# STM32F413 register map
File version: 1.9
CPU: CM4 r0p1, little endian, MPU, FPU, 4 interrupt priority bits
Registers are 32-bit, read-write, reset 0x0 unless marked. A register's access mark holds for its fields unless they carry their own. Offsets are from the block's base; [hi:lo] are bit positions; lines under a group give offsets from that group; {n}, {i} and the like mark numbered series; 'fields as' and 'values as' point back to an identical list.

## IWDG — Independent watchdog
Base 0x40003000
0x00 KR 16-bit wo — Key register
  [15:0] KEY — Key value
    0x5555=Unlock (Enable access to PR, RLR and WINR registers); 0xAAAA=Feed watchdog with RLR register value; 0xCCCC=Start the watchdog
0x04 PR 16-bit — Prescaler register
  [2:0] PR — Prescaler divider
    0=DivideBy4 (Divider /4); 1=DivideBy8 (Divider /8); 2=DivideBy16 (Divider /16); 3=DivideBy32 (Divider /32); 4=DivideBy64 (Divider /64); 5=DivideBy128 (Divider /128); other=DivideBy256 (Divider /256)
0x08 RLR 16-bit reset 0xFFF — Reload register
  [11:0] RL — Watchdog counter reload value
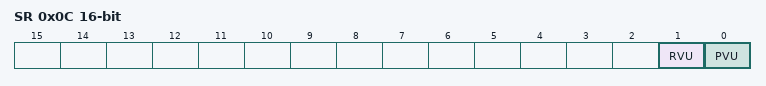
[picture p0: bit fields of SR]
0x0C SR 16-bit ro — Status register
  [1] RVU — Watchdog counter reload value update
  [0] PVU — Watchdog prescaler value update

## RNG — Random number generator
Base 0x50060800
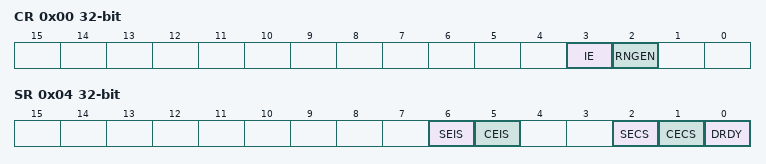
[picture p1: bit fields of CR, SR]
0x00 CR — control register
  [3] IE — Interrupt enable
  [2] RNGEN — Random number generator enable
0x04 SR access per field — status register
  [6] SEIS rw — Seed error interrupt status
  [5] CEIS rw — Clock error interrupt status
  [2] SECS ro — Seed error current status
  [1] CECS ro — Clock error current status
  [0] DRDY ro — Data ready
0x08 DR ro — data register
  [31:0] RNDATA — Random data

## OTG_FS_HOST — USB on the go full speed
Base 0x50000400
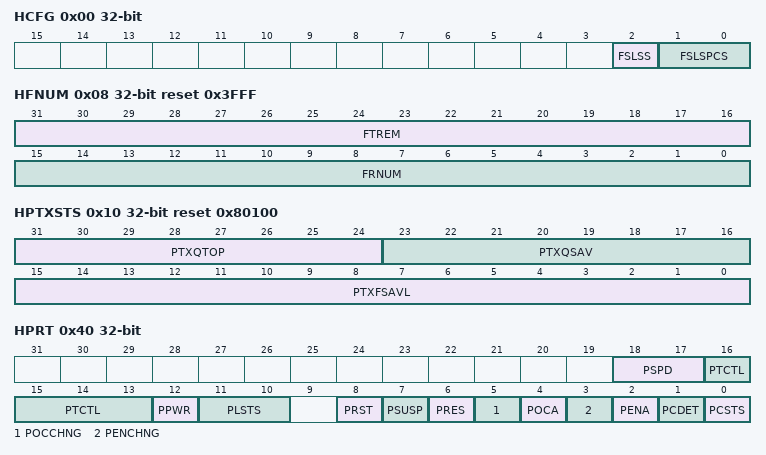
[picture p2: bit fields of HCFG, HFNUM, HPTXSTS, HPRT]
0x00 HCFG — OTG_FS host configuration register (OTG_FS_HCFG)
  [2] FSLSS — FS- and LS-only support
  [1:0] FSLSPCS — FS/LS PHY clock select
0x04 HFIR reset 0xEA60 — OTG_FS Host frame interval register
  [15:0] FRIVL — Frame interval
0x08 HFNUM ro reset 0x3FFF — OTG_FS host frame number/frame time remaining register (OTG_FS_HFNUM)
  [31:16] FTREM — Frame time remaining
  [15:0] FRNUM — Frame number
0x10 HPTXSTS access per field reset 0x80100 — OTG_FS_Host periodic transmit FIFO/queue status register (OTG_FS_HPTXSTS)
  [31:24] PTXQTOP ro — Top of the periodic transmit request queue
  [23:16] PTXQSAV ro — Periodic transmit request queue space available
  [15:0] PTXFSAVL rw — Periodic transmit data FIFO space available
0x14 HAINT ro — OTG_FS Host all channels interrupt register
  [15:0] HAINT — Channel interrupts
0x18 HAINTMSK — OTG_FS host all channels interrupt mask register
  [15:0] HAINTM — Channel interrupt mask
0x40 HPRT access per field — OTG_FS host port control and status register (OTG_FS_HPRT)
  [18:17] PSPD ro — Port speed
  [16:13] PTCTL rw — Port test control
  [12] PPWR rw — Port power
  [11:10] PLSTS ro — Port line status
  [8] PRST rw — Port reset
  [7] PSUSP rw — Port suspend
  [6] PRES rw — Port resume
  [5] POCCHNG rw — Port overcurrent change
  [4] POCA ro — Port overcurrent active
  [3] PENCHNG rw — Port enable/disable change
  [2] PENA rw — Port enable
  [1] PCDET rw — Port connect detected
  [0] PCSTS ro — Port connect status
{0x100+0x20*i} HC{i} (i=0..11) group — Host channel
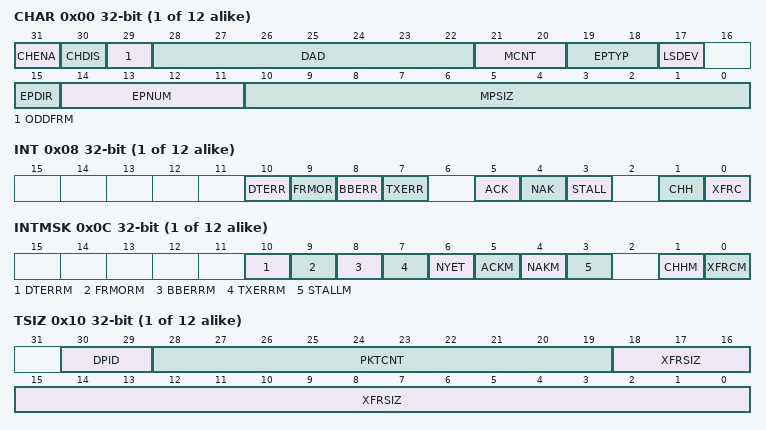
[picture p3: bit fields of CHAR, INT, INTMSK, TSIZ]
  0x00 CHAR — OTG_FS host channel-0 characteristics register (OTG_FS_HCCHAR0)
    [31] CHENA — Channel enable
    [30] CHDIS — Channel disable
    [29] ODDFRM — Odd frame
    [28:22] DAD — Device address
    [21:20] MCNT — Multicount
    [19:18] EPTYP — Endpoint type
    [17] LSDEV — Low-speed device
    [15] EPDIR — Endpoint direction
    [14:11] EPNUM — Endpoint number
    [10:0] MPSIZ — Maximum packet size
  0x08 INT — OTG_FS host channel-0 interrupt register (OTG_FS_HCINT0)
    [10] DTERR — Data toggle error
    [9] FRMOR — Frame overrun
    [8] BBERR — Babble error
    [7] TXERR — Transaction error
    [5] ACK — ACK response received/transmitted interrupt
    [4] NAK — NAK response received interrupt
    [3] STALL — STALL response received interrupt
    [1] CHH — Channel halted
    [0] XFRC — Transfer completed
  0x0C INTMSK — OTG_FS host channel-0 mask register (OTG_FS_HCINTMSK0)
    [10] DTERRM — Data toggle error mask
    [9] FRMORM — Frame overrun mask
    [8] BBERRM — Babble error mask
    [7] TXERRM — Transaction error mask
    [6] NYET — response received interrupt mask
    [5] ACKM — ACK response received/transmitted interrupt mask
    [4] NAKM — NAK response received interrupt mask
    [3] STALLM — STALL response received interrupt mask
    [1] CHHM — Channel halted mask
    [0] XFRCM — Transfer completed mask
  0x10 TSIZ — OTG_FS host channel-0 transfer size register
    [30:29] DPID — Data PID
    [28:19] PKTCNT — Packet count
    [18:0] XFRSIZ — Transfer size

## OTG_FS_PWRCLK — USB on the go full speed
Base 0x50000E00
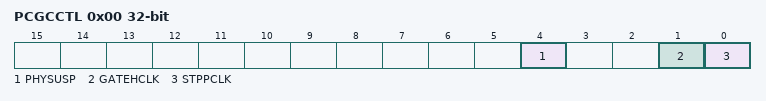
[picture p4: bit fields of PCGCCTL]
0x00 PCGCCTL — OTG_FS power and clock gating control register (OTG_FS_PCGCCTL)
  [4] PHYSUSP — PHY Suspended
  [1] GATEHCLK
  [0] STPPCLK — Stop PHY clock

## WWDG — Window watchdog
Base 0x40002C00
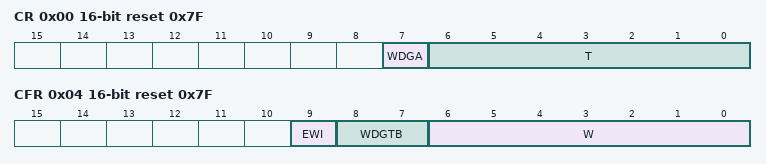
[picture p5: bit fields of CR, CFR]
0x00 CR 16-bit reset 0x7F — Control register
  [7] WDGA — Activation bit
    0=Disabled (Watchdog disabled); 1=Enabled (Watchdog enabled)
  [6:0] T — 7-bit counter (MSB to LSB)
0x04 CFR 16-bit reset 0x7F — Configuration register
  [9] EWI — Early wakeup interrupt
    on write: 1=Enable (interrupt occurs whenever the counter reaches the value 0x40)
  [8:7] WDGTB — Timer base
    0=Div1 (Counter clock (PCLK1 div 4096) div 1); 1=Div2 (Counter clock (PCLK1 div 4096) div 2); 2=Div4 (Counter clock (PCLK1 div 4096) div 4); 3=Div8 (Counter clock (PCLK1 div 4096) div 8)
  [6:0] W — 7-bit window value
0x08 SR 16-bit — Status register
  [0] EWIF write-0-clears — Early wakeup interrupt flag
    on read: 0=Finished (The EWI Interrupt Service Routine has been serviced); 1=Pending (The EWI Interrupt Service Routine has been triggered) | on write: 0=Finished (The EWI Interrupt Service Routine has been serviced)

## ADC_Common — ADC common registers
Base 0x40012300
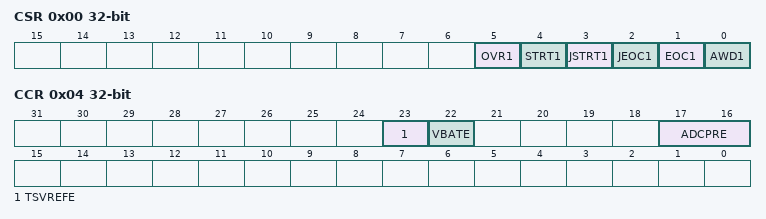
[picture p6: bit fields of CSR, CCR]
0x00 CSR ro — ADC Common status register
  [5] OVR1 — Overrun flag of ADC 1
    0=No overrun occurred; 1=Overrun occurred
  [4] STRT1 — Regular channel Start flag of ADC 1
    0=NotStarted (No regular channel conversion started); 1=Started (Regular channel conversion has started)
  [3] JSTRT1 — Injected channel Start flag of ADC 1
    0=NotStarted (No injected channel conversion started); 1=Started (Injected channel conversion has started)
  [2] JEOC1 — Injected channel end of conversion of ADC 1
    0=NotComplete (Conversion is not complete); 1=Complete (Conversion complete)
  [1] EOC1 — End of conversion of ADC 1
    values as JEOC1
  [0] AWD1 — Analog watchdog flag of ADC 1
    0=NoEvent (No analog watchdog event occurred); 1=Event (Analog watchdog event occurred)
0x04 CCR — ADC common control register
  [23] TSVREFE — Temperature sensor and VREFINT enable
    0=Disabled (Temperature sensor and V_REFINT channel disabled); 1=Enabled (Temperature sensor and V_REFINT channel enabled)
  [22] VBATE — VBAT enable
    0=Disabled (V_BAT channel disabled); 1=Enabled (V_BAT channel enabled)
  [17:16] ADCPRE — ADC prescaler
    0=Div2 (PCLK2 divided by 2); 1=Div4 (PCLK2 divided by 4); 2=Div6 (PCLK2 divided by 6); 3=Div8 (PCLK2 divided by 8)
